# TinyRocket register map
File version: 0.8
TinyRocket on Arty
CPU: RISCV rv32imac, little endian, no MPU, no FPU, 4 interrupt priority bits
Registers are 32-bit, read-write, reset 0x0 unless marked. A register's access mark holds for its fields unless they carry their own. Offsets are from the block's base; lines under a group give offsets from that group; [hi:lo] are bit positions; {n}, {i} and the like mark numbered series; 'fields as' and 'values as' point back to an identical list; <NAME> marks a mode.

## Memory map
0x00004000 BOOT_SELECT size 0x400 — Boot Selection Pin
0x00100000 RCC size 0x400 — Reset and Clock Control
0x02000000 CLINT size 0x400 — Core-Local Interruptor
0x0C000000 PLIC size 0x201000 — Platform Level Interrupt Controller
0x10013000 UART0 size 0x400 — Universal Asynchronous Receiver/Transmitter

## BOOT_SELECT — Boot Selection Pin
Base 0x00004000
0x00 BOOT_SEL ro — boot select
  [0] VAL0 — Input value of pin 0
    1=Self-Boot Mode; 0=Tethered Boot Mode

## RCC — Reset and Clock Control
Base 0x00100000
0x00 TILE0_RESET — RocketTile 0 reset control
  [0] TILE0_RESET

## CLINT — Core-Local Interruptor
Base 0x02000000
0x00 MSIP0 — hart 0 msip bit
  [0] MSIP0 — hart 0 machine mode software interrupt in progress
    1=Interrupt pending (Self-Boot Mode); 0=No interrupt (Tethered Boot Mode)
0x4000 MTIMECMP0 — hart 0 mtimecmp value
  [63:0] MTIMECMP0 — hart 0 machine mode timer compare value
0xBFF8 MTIME — mtime value
  [63:0] MTIME — machine mode timer value

## PLIC — Platform Level Interrupt Controller
Base 0x0C000000
{0x0+4i} PRIO{i} (i=0..3) — priority {i}
  [2:0] PRIO{i} — source {i} priority
0x08 PRIO4 — priority 4
  [2:0] PRIO4 — source 4 priority
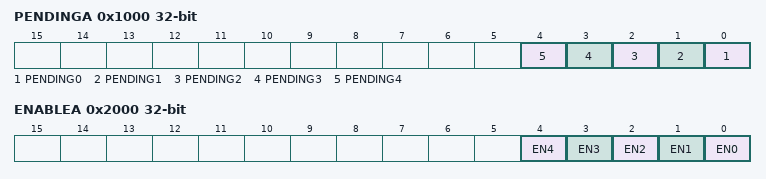
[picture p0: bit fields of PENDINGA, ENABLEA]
0x1000 PENDINGA ro
  [all] fields
    1=Pending (Interrupt pending); 0=Not pending (No interrupt pending)
  [n] PENDING{n} (n=0..4) — source {n} pending status
0x2000 ENABLEA
  [all] fields
    1=Enabled (Interrupt enabled); 0=Disabled (Interrupt disabled)
  [n] EN{n} (n=0..4) — source {n} enable
0x200000 THRESHOLD
  [2:0] THRESHOLD — priority threshold

## UART0 — Universal Asynchronous Receiver/Transmitter
Base 0x10013000
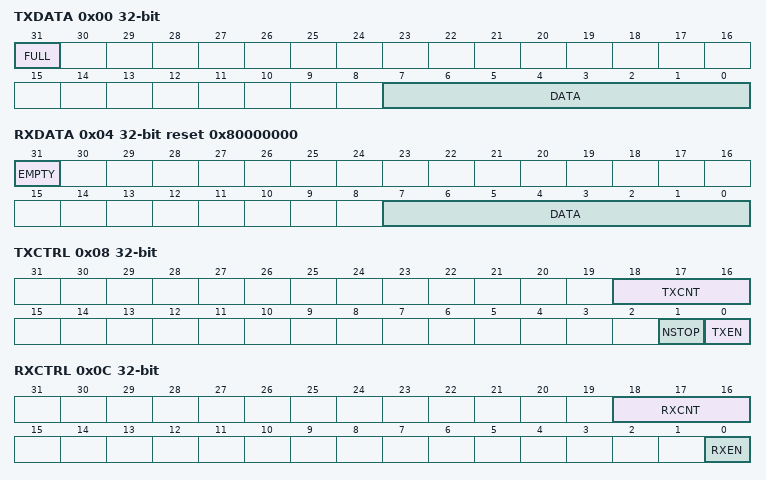
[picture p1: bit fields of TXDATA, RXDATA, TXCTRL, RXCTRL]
0x00 TXDATA — transmit data register
  [31] FULL — Transmit FIFO full
    1=Full (Transmit FIFO is full); 0=Not full (Transmit FIFO is not full)
  [7:0] DATA — Transmit data
0x04 RXDATA ro reset 0x80000000 — receive data register
  [31] EMPTY — Receive FIFO empty
    1=Empty (Receive FIFO is empty); 0=Not empty (Receive FIFO is not empty)
  [7:0] DATA — Received data
0x08 TXCTRL — transmit control register
  [18:16] TXCNT — Transmit watermark level
  [1] NSTOP — Number of stop bits
    1=2 stop bits; 0=1 stop bit
  [0] TXEN — Transmit enable
    1=Enabled (Transmit enabled); 0=Disabled (Transmit disabled)
0x0C RXCTRL — receive control register
  [18:16] RXCNT — Receive watermark level
  [0] RXEN — Receive enable
    1=Enabled (Receive enabled); 0=Disabled (Receive disabled)
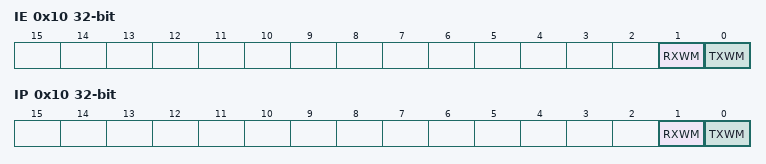
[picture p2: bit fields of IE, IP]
0x10 IE — interrupt enable register
  [1] RXWM — Receive watermark interrupt enable
    1=Enabled (RX watermark interrupt enabled); 0=Disabled (RX watermark interrupt disabled)
  [0] TXWM — Transmit watermark interrupt enable
    1=Enabled (TX watermark interrupt enabled); 0=Disabled (TX watermark interrupt disabled)
0x10 IP ro — interrupt pending register
  [1] RXWM — Receive watermark interrupt pending
    1=Pending (RX watermark interrupt pending); 0=Not pending (RX watermark interrupt not pending)
  [0] TXWM — Transmit watermark interrupt pending
    1=Pending (TX watermark interrupt pending); 0=Not pending (TX watermark interrupt not pending)
0x18 DIV reset 0xAD — baudrate divisor
  [15:0] DIV — Baudrate divisor
